AUTOSAR XML (schema 4-3-0)
package /CollisionDetectionBSW/Services/Os
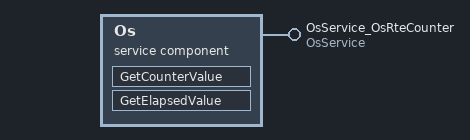
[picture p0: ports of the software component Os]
  service sw component type Os
    provide port OsService_OsRteCounter: provided-interface=OsService
    behavior OsBehavior: handle-termination-and-restart=NO-SUPPORT, port-api-option{port-defined-argument-value{value=CounterType:0, value-type=CounterType}, port=OsService_OsRteCounter}
      operation invoked event GetCounterValue_OsService_OsRteCounter_GetCounterValue: start-on-event=GetCounterValue, operation=OsService_OsRteCounter.GetCounterValue
      operation invoked event GetElapsedValue_OsService_OsRteCounter_GetElapsedValue: start-on-event=GetElapsedValue, operation=OsService_OsRteCounter.GetElapsedValue
      runnable GetCounterValue: symbol=Os_GetCounterValue
      runnable GetElapsedValue: symbol=Os_GetElapsedValue
  swc implementation OsImpl: programming-language=C, vendor-id=60, behavior=OsBehavior
    code-descriptors:
      code src: artifact-descriptors=autosar-engineering-object={short-label=artifactDescriptor, category=artifactDescriptorCategory}
    resource consumption resourceConsumption
